# STM32C031 register map
File version: 1.2
CPU: CM0 r0p0, little endian, MPU, FPU, 2 interrupt priority bits
Registers are 32-bit, read-write, reset 0x0 unless marked. A register's access mark holds for its fields unless they carry their own. Offsets are from the block's base; lines under a group give offsets from that group; [hi:lo] are bit positions; {n}, {i} and the like mark numbered series; 'fields as' and 'values as' point back to an identical list; <NAME> marks a mode.

## Memory map
0x40000400 TIM3 size 0x400 — General-purpose timer
0x40002000 TIM14 size 0x400 — General-purpose timers
0x40002800 RTC size 0x400 — RTC register block
0x40002C00 WWDG size 0x400 — WWDG register block
0x40003000 IWDG size 0x400 — IWDG register block
0x40004400 USART2 size 0x400
0x40005400 I2C1 size 0x400 — I2C register block
0x40007000 PWR size 0x400 — PWR address block description
0x40010000 SYSCFG size 0x400 — SYSCFG register block
0x40012400 ADC size 0x400 — Analog to Digital Converter
0x40012C00 TIM1 size 0x400 — Advanced-control timer
0x40013000 SPI1 size 0x400 — Serial peripheral interface
0x40013800 USART1 size 0x400 — USART register block
0x40014400 TIM16 size 0x400 — General-purpose timers
0x40014800 TIM17 size 0x400 — General-purpose timers
0x40015800 DBG size 0x400 — DBG register block
0x40020000 DMA size 0x400 — DMA controller
0x40020800 DMAMUX size 0x800 — DMAMUX register block
0x40021000 RCC size 0x400 — RCC address block description
0x40021800 EXTI size 0x400 — EXTI address block description
0x40022000 FLASH size 0x400 — Spider_FLASH register block
0x40023000 CRC size 0x400 — Cyclic redundancy check calculation unit
0x50000000 GPIOA size 0x400 — GPIOA address block description
0x50000400 GPIOB size 0x400 — GPIOB address block description
0x50000800 GPIOC size 0x400 — GPIOC address block description
0x50000C00 GPIOD size 0x400 — GPIOD address block description
0x50001400 GPIOF size 0x400 — GPIOF address block description

## Interrupts
0 WWDG — Window watchdog interrupt
1 PVM (EXTI) — VDDIO2 monitor interrupt (EXTI line 34
2 RTC — RTC interrupts (EXTI lines 19)
3 FLASH — Flash global interrupt
4 RCC — RCC global interrupt
5 EXTI0_1 (EXTI) — EXTI line 0 and 1 interrupt
6 EXTI2_3 (EXTI) — EXTI line 2 and 3 interrupt
7 EXTI4_15 (EXTI) — EXTI line 4 and 15 interrupt
9 DMA1_Channel1 (DMA) — DMA1 channel 1 interrupt
10 DMA1_Channel2_3 (DMA) — DMA1 channel 2 and 3 interrupts
11 DMAMUX_DMA1_Channel4_5 (DMAMUX) — DMAMUX and DMA1 channel 4 and 5 interrupts
12 ADC — ADC interrupt
13 TIM1_BRK_UP_TRG_COM (TIM1) — TIM1 break, update, trigger and commutation interrupts
14 TIM1_CC (TIM1) — TIM1 Capture Compare interrupt
16 TIM3 — TIM3 gloabal interrupt
19 TIM14 — TIM14 gloabal interrupt
21 TIM16 — TIM16 global interrupt
22 TIM17 — TIM17 global interrupt
23 I2C (I2C1) — global interrupt (combined with EXTI 23)
25 SPI (SPI1) — SPI/I2S global interrupt
27 USART1 — USART1 global interrupt (combined with EXTI 25)
28 USART2 — USART2 global interrupt (combined with EXTI 25)

## CRC — Cyclic redundancy check calculation unit
Base 0x40023000
0x00 DR reset 0xFFFFFFFF — CRC data register
  [31:0] DR — Data register bits This register is used to write new data to the CRC calculator. It holds the previous CRC calculation result when it is read. If the data size is less than 32 bits, the least significant bits are used to write/read the correct value.
0x00 DR8 8-bit reset 0xFF (alternate view of DR) — Data register - byte sized
  [7:0] DR8 — Data register bits
0x00 DR16 16-bit reset 0xFFFF (alternate view of DR) — Data register - half-word sized
  [15:0] DR16 — Data register bits
0x04 IDR — CRC independent data register
  [31:0] IDR — General-purpose 32-bit data register bits
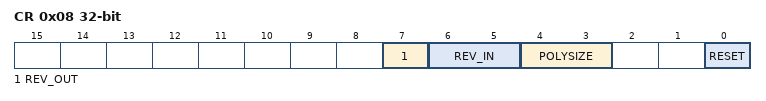
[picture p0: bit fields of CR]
0x08 CR — CRC control register
  [7] REV_OUT — Reverse output data This bit controls the reversal of the bit order of the output data.
    0=Normal (Bit order not affected); 1=Reversed (Bit reversed output)
  [6:5] REV_IN — Reverse input data These bits control the reversal of the bit order of the input data
    0=Normal (Bit order not affected); 1=Byte (Bit reversal done by byte); 2=HalfWord (Bit reversal done by half-word); 3=Word (Bit reversal done by word)
  [4:3] POLYSIZE — Polynomial size These bits control the size of the polynomial.
    0=32-bit polynomial; 1=16-bit polynomial; 2=8-bit polynomial; 3=7-bit polynomial
  [0] RESET — RESET bit This bit is set by software to reset the CRC calculation unit and set the data register to the value stored in the CRC_INIT register. This bit can only be set, it is automatically cleared by hardware
    on write: 1=Resets the CRC calculation unit and sets the data register to 0xFFFF FFFF
0x10 INIT reset 0xFFFFFFFF — CRC initial value
  [31:0] INIT — Programmable initial CRC value This register is used to write the CRC initial value.
0x14 POL reset 0x4C11DB7 — CRC polynomial
  [31:0] POL — Programmable polynomial This register is used to write the coefficients of the polynomial to be used for CRC calculation. If the polynomial size is less than 32 bits, the least significant bits have to be used to program the correct value.
